# PIC32MX210F016D register map
Vendor: Microchip
Architecture 32xxxx. Special function registers and configuration words.
Registers are 32-bit, read-write, reset 0x0 unless marked. A register's access mark holds for its fields unless they carry their own. Addresses are absolute, and some are shared; only a register's first bit layout is shown; lines under a group give offsets from that group; [hi:lo] are bit positions; {n}, {i} and the like mark numbered series; 'fields as' and 'values as' point back to an identical list; <NAME> marks a mode.

## Further device data
pins=1: RB9/PMD3/CTED4/SDA1/RPB9; 2: RC6/PMA1/RPC6; 3: RC7/PMA0/RPC7; 4: RC8/PMA5/RPC8; 5: RC9/PMA6/CTED7/RPC9; 6: VSS; 7: VCAP; 8: RB10/CTED11/D+/RPB10/PGED2; 9: RB11/D-/RPB11/PGEC2; 10: VUSB3V3; 11: RB13/PMRD/CTPLS/RPB13/AN11; 12: RA10/PMA10/TMS/PGED4; 13: RA7/PMA7/CTED8/TCK/PGEC4; 14: RB14/CTED5/SCK1/VBUSON/RPB14/C3INB/AN10/CVREFOUT; 15: RB15/PMCS1/CTED6/SCK2/RPB15/C3INA/AN9; 16: AVSS; 17: AVDD; 18: MCLR; 19: RA0/PMD7/CTED1/RPA0/C3INC/AN0/VREF+/PGED3; 20: RA1/PMD6/CTED2/RPA1/AN1/VREF-/PGEC3; 21: RB0/PMD0/RPB0/C3IND/C2INB/C1IND/AN2/PGED1; 22: RB1/PMD1/CTED12/RPB1/C2INA/C1INC/AN3/PGEC1; 23: RB2/PMD2/CTED13/SDA2/RPB2/C2IND/C1INB/AN4; 24: RB3/PMWR/SCL2/RPB3/RTCC/C2INC/C1INA/AN5; 25: RC0/RPC0/AN6; 26: RC1/RPC1/AN7; 27: RC2/PMA2/RPC2/AN8; 28: VDD; 29: VSS; 30: RA2/RPA2/CLKI/OSC1; 31: RA3/RPA3/CLKO/OSC2; 32: RA8/PMA8/RPA8/TDO; 33: RB4/RPB4/SOSCI; 34: RA4/CTED9/T1CK/RPA4/SOSCO; 35: RA9/PMA9/RPA9/TDI; 36: RC3/RPC3/AN12; 37: RC4/PMA4/RPC4; 38: RC5/PMA3/RPC5; 39: VSS; 40: VDD; 41: RB5/USBID/RPB5; 42: VBUS; 43: RB7/INT0/PMD5/CTED3/RPB7; 44: RB8/PMD4/CTED10/SCL1/RPB8, interrupts=0 CORE_TIMER — Core Timer; 1 CORE_SOFTWARE_0 — Core Software 0; 2 CORE_SOFTWARE_1 — Core Software 1; 3 EXTERNAL_0 — Ext INT 0; 4 TIMER_1 — Timer1; 5 INPUT_CAPTURE_1 — Input Capture 1; 6 OUTPUT_COMPARE_1 — Output Compare 1; 7 EXTERNAL_1 — Ext INT 1; 8 TIMER_2 — Timer2; 9 INPUT_CAPTURE_2 — Input Capture 2; 10 OUTPUT_COMPARE_2 — Output Compare 2; 11 EXTERNAL_2 — Ext INT 2; 12 TIMER_3 — Timer3; 13 INPUT_CAPTURE_3 — Input Capture 3; 14 OUTPUT_COMPARE_3 — Output Compare 3; 15 EXTERNAL_3 — Ext INT 3; 16 TIMER_4 — Timer4; 17 INPUT_CAPTURE_4 — Input Capture 4; 18 OUTPUT_COMPARE_4 — Output Compare 4; 19 EXTERNAL_4 — Ext INT 4; 20 TIMER_5 — Timer5; 21 INPUT_CAPTURE_5 — Input Capture 5; 22 OUTPUT_COMPARE_5 — Output Compare 5; 23 ADC — ADC; 24 FAIL_SAFE_MONITOR — Fail Safe Clock Monitor; 25 RTCC — Real Time Clock Calendar; 26 FCE — Flash Control Event; 27 COMPARATOR_1 — Comparator 1; 28 COMPARATOR_2 — Comparator 2; 29 COMPARATOR_3 — Comparator 3; 30 USB_1 — USB Module 1; 31 SPI_1 — SPI1; 32 UART_1 — UART 1; 33 I2C_1 — I2C 1; 34 CHANGE_NOTICE — Change Notice; 35 PMP — PMP; 36 SPI_2 — SPI 2; 37 UART_2 — UART 2; 38 I2C_2 — I2C 2; 39 CTMU — CTMU Event; 40 DMA_0 — DMA Channel 0; 41 DMA_1 — DMA Channel 1; 42 DMA_2 — DMA Channel 2; 43 DMA_3 — DMA Channel 3

## WDT
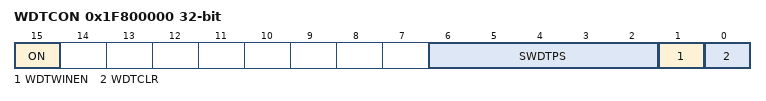
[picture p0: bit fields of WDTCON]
0x1F800000 WDTCON reset not defined — (power-on value ----------------0--------00000x0)
  [15] ON, [6:2] SWDTPS ro, [1] WDTWINEN, [0] WDTCLR

## RTCC
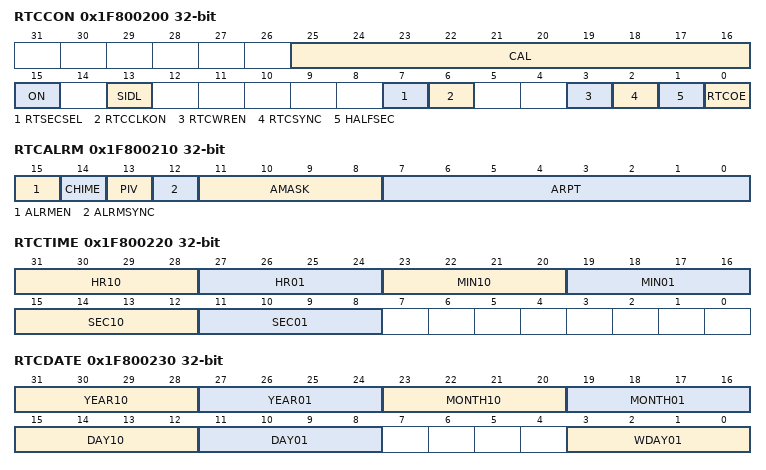
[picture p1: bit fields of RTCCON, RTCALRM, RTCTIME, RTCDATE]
0x1F800200 RTCCON
  [25:16] CAL, [15] ON, [13] SIDL, [7] RTSECSEL, [6] RTCCLKON, [3] RTCWREN, [2] RTCSYNC ro, [1] HALFSEC ro, [0] RTCOE
0x1F800210 RTCALRM
  [15] ALRMEN, [14] CHIME, [13] PIV, [12] ALRMSYNC, [11:8] AMASK, [7:0] ARPT
0x1F800220 RTCTIME reset not defined — (power-on value 000xxxxxxxxxxxxx0xxxxxxx--------)
  [31:28] HR10, [27:24] HR01, [23:20] MIN10, [19:16] MIN01, [15:12] SEC10, [11:8] SEC01
0x1F800230 RTCDATE reset not defined — (power-on value xxxxxxxx000xxxxx00xxxxxx----0xxx)
  [31:28] YEAR10, [27:24] YEAR01, [23:20] MONTH10, [19:16] MONTH01, [15:12] DAY10, [11:8] DAY01, [3:0] WDAY01
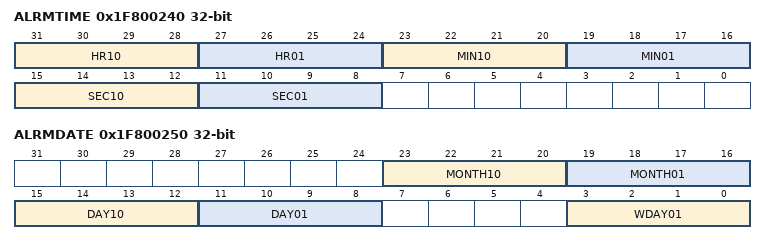
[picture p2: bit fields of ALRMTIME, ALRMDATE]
0x1F800240 ALRMTIME reset not defined — (power-on value 000xxxxx0xxxxxxx0xxxxxxx--------)
  fields as RTCTIME
0x1F800250 ALRMDATE reset not defined — (power-on value --------000xxxxx00xxxxxx----0xxx)
  [23:20] MONTH10, [19:16] MONTH01, [15:12] DAY10, [11:8] DAY01, [3:0] WDAY01
